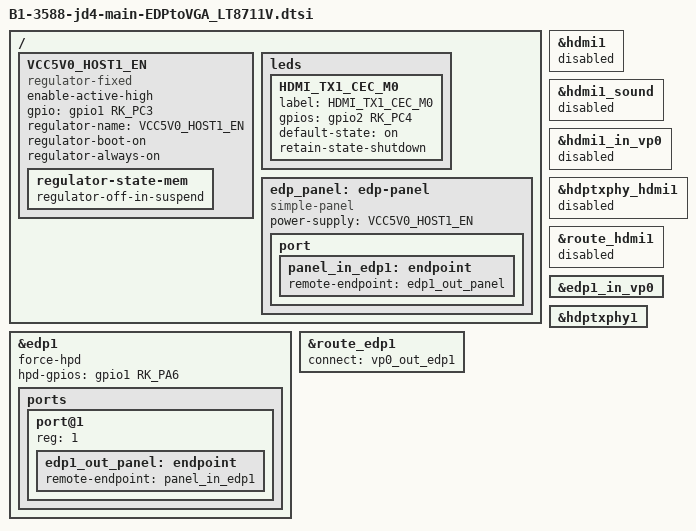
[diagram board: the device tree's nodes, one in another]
// SPDX-License-Identifier: (GPL-2.0+ OR MIT)
/*
 * Copyright (c) 2021 Rockchip Electronics Co., Ltd.
 *
 */

 / {

    VCC5V0_HOST1_EN: VCC5V0_HOST1_EN {
        compatible = "regulator-fixed";
        enable-active-high;
        gpio =  <&gpio1 RK_PC3 GPIO_ACTIVE_HIGH>;

        regulator-name = "VCC5V0_HOST1_EN";
        regulator-boot-on;

        regulator-always-on;
        regulator-state-mem {
            regulator-off-in-suspend;
        };
    };

    // HDMI_TX1_CEC_M0: HDMI_TX1_CEC_M0 {
    //     compatible = "regulator-fixed";
    //     enable-active-high;
    //     gpio =  <&gpio2 RK_PC4 GPIO_ACTIVE_HIGH>;

    //     regulator-name = "HDMI_TX1_CEC_M0";
    //     regulator-boot-on;

    //     regulator-always-on;
    //     regulator-state-mem {
    //         regulator-off-in-suspend;
    //     };
    // };

    leds {
        HDMI_TX1_CEC_M0: HDMI_TX1_CEC_M0{
			label = "HDMI_TX1_CEC_M0";
			gpios = <&gpio2 RK_PC4 GPIO_ACTIVE_HIGH>;
			default-state = "on";
			retain-state-shutdown;
		};
    };

    edp_panel: edp-panel {
        compatible = "simple-panel";
        status = "okay";
        power-supply = <&VCC5V0_HOST1_EN>;

        // panel-timing {
        //     clock-frequency = <140000000>;
        //     hactive = <1920>;
        //     vactive = <1080>;
        //     hfront-porch = <12>;
        //     hsync-len = <16>;
        //     hback-porch = <48>;
        //     vfront-porch = <8>;
        //     vsync-len = <4>;
        //     vback-porch = <8>;
        //     hsync-active = <0>;
        //     vsync-active = <0>;
        //     de-active = <0>;
        //     pixelclk-active = <0>;
        // };

        port {
            panel_in_edp1: endpoint {
                remote-endpoint = <&edp1_out_panel>;
            };
        };
    };
 };

&hdmi1 {
	status = "disabled";
};

&hdmi1_sound {
	status = "disabled";
};

&hdmi1_in_vp0 {
    status = "disabled";
};

&hdptxphy_hdmi1 {
	status = "disabled";
};

&route_hdmi1{
	status = "disabled";
};

&edp1{
    force-hpd;
    hpd-gpios = <&gpio1 RK_PA6 GPIO_ACTIVE_HIGH>;
    status = "okay";
    ports {
        port@1 {
            reg = <1>;
            edp1_out_panel: endpoint {
                remote-endpoint = <&panel_in_edp1>;
            };
        };
    };
};

&edp1_in_vp0{
    status = "okay";
};

&hdptxphy1 {
    status = "okay";
};

&route_edp1 {
    status = "okay";
    connect = <&vp0_out_edp1>;
};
